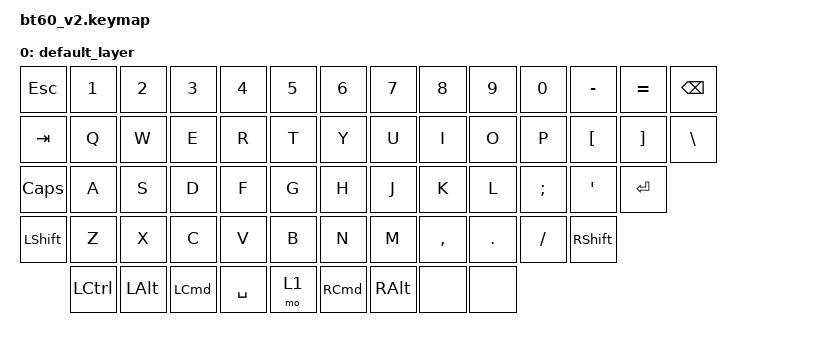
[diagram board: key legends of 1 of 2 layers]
/*
 * Copyright (c) 2020 The ZMK Contributors
 *
 * SPDX-License-Identifier: MIT
 */


/* THIS FILE WAS GENERATED!
 *
 * This file was generated automatically. You may or may not want to
 * edit it directly.
 */

#include <behaviors.dtsi>
#include <dt-bindings/zmk/keys.h>
#include <dt-bindings/zmk/outputs.h>
#include <dt-bindings/zmk/bt.h>
#include <dt-bindings/zmk/rgb.h>

/ {
    keymap {
        compatible = "zmk,keymap";


        default_layer {
            bindings = <
                &kp ESC       &kp N1            &kp N2            &kp N3             &kp N4            &kp N5                             &kp N6                 &kp N7             &kp N8        &kp N9    &kp N0      &kp MINUS     &kp EQUAL      &kp BACKSPACE
                &kp TAB       &kp Q             &kp W             &kp E              &kp R             &kp T                              &kp Y                  &kp U              &kp I         &kp O     &kp P       &kp LBKT      &kp RBKT       &kp BACKSLASH
                &kp CAPS      &kp A             &kp S             &kp D              &kp F             &kp G                              &kp H                  &kp J              &kp K         &kp L     &kp SEMI    &kp SQT       &kp RET
                &kp LSHFT     &kp Z             &kp X             &kp C              &kp V             &kp B                              &kp N                  &kp M              &kp COMMA     &kp DOT   &kp FSLH    &kp RSHFT
                              &kp LEFT_CONTROL  &kp LEFT_ALT      &kp LEFT_COMMAND   &kp SPACE         &mo 1                              &kp RIGHT_COMMAND      &kp RIGHT_ALT      &none         &none
            >;
        };

        layer_raise {
            bindings = <
                &kp GRAVE     &kp F1      &kp F2      &kp F3      &kp F4      &kp F5                             &kp F6              &kp F7          &kp F8      &kp F9              &kp F10             &kp F11             &kp F12         &kp DEL
                &out OUT_TOG  &trans      &trans      &trans      &trans      &trans                             &trans              &trans          &trans      &trans              &trans              &kp HOME              &kp END          &trans
                &trans        &trans      &trans      &trans      &trans      &trans                             &trans              &trans          &kp LEFT_ARROW &kp DOWN_ARROW   &kp UP_ARROW        &kp RIGHT_ARROW     &sys_reset
                &trans        &none       &trans      &trans      &trans      &trans                             &bt BT_PRV          &bt BT_NXT      &trans      &trans              &trans              &trans              
                              &trans      &trans      &trans      &trans                                         &trans              &trans          &trans      &bt BT_CLR
            >;
        };

    };
};
